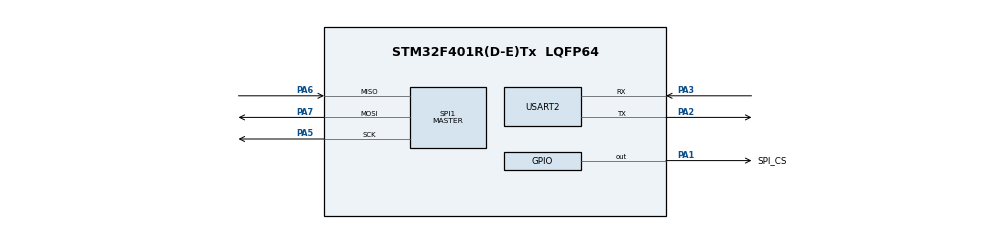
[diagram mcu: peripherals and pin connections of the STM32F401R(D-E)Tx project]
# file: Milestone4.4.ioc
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Mcu.Family=STM32F4
Mcu.Name=STM32F401R(D-E)Tx
Mcu.Package=LQFP64
NVIC.PriorityGroup=NVIC_PRIORITYGROUP_4
PA1.GPIO_Label=SPI_CS
PA1.GPIO_Speed=GPIO_SPEED_FREQ_VERY_HIGH
PA1.PinState=GPIO_PIN_SET
PA1.Signal=GPIO_Output
PA2.Mode=Asynchronous
PA2.Signal=USART2_TX
PA3.Mode=Asynchronous
PA3.Signal=USART2_RX
PA5.Mode=Full_Duplex_Master
PA5.Signal=SPI1_SCK
PA6.Mode=Full_Duplex_Master
PA6.Signal=SPI1_MISO
PA7.Mode=Full_Duplex_Master
PA7.Signal=SPI1_MOSI
ProjectManager.HeapSize=0x200
ProjectManager.StackSize=0x400
ProjectManager.TargetToolchain=Makefile
RCC.AHBFreq_Value=16000000
RCC.APB1Freq_Value=16000000
RCC.APB2Freq_Value=16000000
RCC.CortexFreq_Value=16000000
RCC.HSE_VALUE=25000000
RCC.HSI_VALUE=16000000
RCC.LSE_VALUE=32768
RCC.SYSCLKFreq_VALUE=16000000
RCC.VCOOutputFreq_Value=192000000
SPI1.Direction=SPI_DIRECTION_2LINES
SPI1.Mode=SPI_MODE_MASTER
SPI1.VirtualType=VM_MASTER
USART2.VirtualMode=VM_ASYNC
board=custom

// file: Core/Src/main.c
/* USER CODE BEGIN Header */
/**
  ******************************************************************************
  * @file           : main.c
  * @brief          : Main program body
  ******************************************************************************
  * @attention
  *
  * Copyright (c) 2026 STMicroelectronics.
  * All rights reserved.
  *
  * This software is licensed under terms that can be found in the LICENSE file
  * in the root directory of this software component.
  * If no LICENSE file comes with this software, it is provided AS-IS.
  *
  ******************************************************************************
  */
/* USER CODE END Header */
#include "main.h"
#include <stddef.h>
#include <string.h>

void UART_SendAndReadData(USART_TypeDef *USARTX, const uint8_t *data, size_t length);
void FGPA_WriteRegister(uint8_t addr, uint8_t write);
uint8_t FGPA_ReadRegister(uint8_t addr);

void SystemClock_Config(void);
static void MX_GPIO_Init(void);
static void MX_SPI1_Init(void);
static void MX_USART2_UART_Init(void);

int main(void)
{

  /* MCU Configuration--------------------------------------------------------*/

  /* Reset of all peripherals, Initializes the Flash interface and the Systick. */
  LL_APB2_GRP1_EnableClock(LL_APB2_GRP1_PERIPH_SYSCFG);
  LL_APB1_GRP1_EnableClock(LL_APB1_GRP1_PERIPH_PWR);

  /* System interrupt init*/
  NVIC_SetPriorityGrouping(NVIC_PRIORITYGROUP_4);

  /* SysTick_IRQn interrupt configuration */
  NVIC_SetPriority(SysTick_IRQn, NVIC_EncodePriority(NVIC_GetPriorityGrouping(),15, 0));

  /* Configure the system clock */
  SystemClock_Config();

  /* Initialize all configured peripherals */
  MX_GPIO_Init();
  MX_SPI1_Init();
  MX_USART2_UART_Init();
  /* USER CODE BEGIN 2 */
  LL_SPI_Enable(SPI1);

  /* USER CODE END 2 */

  uint8_t addr = 0x02;

  uint8_t write = 0x03;

  uint8_t debug_a = 'A';
  uint8_t debug_b = 'B';
  uint8_t debug_c = 'C';

 // UART_SendAndReadData(USART2, &debug_a, 1);

  FGPA_WriteRegister(addr, write);

//  UART_SendAndReadData(USART2, &debug_b, 1);

  uint8_t test = FGPA_ReadRegister(addr);

//  UART_SendAndReadData(USART2, &debug_c, 1);

  UART_SendAndReadData(USART2, &test, 1);
  /* Infinite loop */
  while (1)
  {

  }
}
uint8_t FGPA_ReadRegister(uint8_t addr){

    uint8_t rx_data = 0x00 | (addr & 0x7F);
    uint8_t dummy_byte = 0x00;
    uint8_t dummy_rx;
    uint8_t byte_data;
    (void)dummy_rx;

    // Read Function for
    LL_GPIO_ResetOutputPin(GPIOA, LL_GPIO_PIN_1);
    while (!LL_SPI_IsActiveFlag_TXE(SPI1)){}
      LL_SPI_TransmitData8(SPI1, rx_data);
   //  while (LL_SPI_IsActiveFlag_BSY(SPI1)){}

    while (!LL_SPI_IsActiveFlag_RXNE(SPI1)){}
    dummy_rx = LL_SPI_ReceiveData8(SPI1);

    while (!LL_SPI_IsActiveFlag_TXE(SPI1)){}

    LL_SPI_TransmitData8(SPI1, dummy_byte);

    while (!LL_SPI_IsActiveFlag_RXNE(SPI1)){}

    byte_data = LL_SPI_ReceiveData8(SPI1);

    while (LL_SPI_IsActiveFlag_BSY(SPI1)){}

    LL_GPIO_SetOutputPin(GPIOA, LL_GPIO_PIN_1);

    return byte_data;

}

void UART_SendAndReadData(USART_TypeDef *USARTX, const uint8_t *data, size_t length){

  for (size_t i = 0; i < length; i++){
   while (!LL_USART_IsActiveFlag_TXE(USARTX));
   LL_USART_TransmitData8(USARTX, data[i]);
   //while(!LL_USART_IsActiveFlag_RXNE(USART1)){}
  //  LL_USART_ReceiveData8(USART1);
  }
 // while (!LL_USART_IsActiveFlag_TXE(USARTX));
//  LL_USART_TransmitData8(USARTX, '\n');
  while (!LL_USART_IsActiveFlag_TC(USARTX)){}
  //while(!LL_USART_IsActiveFlag_RXNE(USART1)){}
  //LL_USART_ReceiveData8(USART1);
}

void FGPA_WriteRegister(uint8_t addr, uint8_t write){
    uint8_t tx_data = 0x80 | (addr & 0x7F);
    uint8_t dummy_byte;
    uint8_t dummy_tx;
    (void)dummy_tx;
    (void) dummy_byte;

    LL_GPIO_ResetOutputPin(GPIOA, LL_GPIO_PIN_1);
    while (!LL_SPI_IsActiveFlag_TXE(SPI1)){}

    LL_SPI_TransmitData8(SPI1, tx_data);

    while (!LL_SPI_IsActiveFlag_RXNE(SPI1)){}

    dummy_byte = LL_SPI_ReceiveData8(SPI1);

    while (!LL_SPI_IsActiveFlag_TXE(SPI1)){}

    LL_SPI_TransmitData8(SPI1, write);

    while (!LL_SPI_IsActiveFlag_RXNE(SPI1)){}

    dummy_tx = LL_SPI_ReceiveData8(SPI1);

    while (LL_SPI_IsActiveFlag_BSY(SPI1)){}

    LL_GPIO_SetOutputPin(GPIOA, LL_GPIO_PIN_1);
}

void SystemClock_Config(void)
{
  LL_FLASH_SetLatency(LL_FLASH_LATENCY_0);
  while(LL_FLASH_GetLatency()!= LL_FLASH_LATENCY_0)
  {
  }
  LL_PWR_SetRegulVoltageScaling(LL_PWR_REGU_VOLTAGE_SCALE2);
  LL_RCC_HSI_SetCalibTrimming(16);
  LL_RCC_HSI_Enable();

   /* Wait till HSI is ready */
  while(LL_RCC_HSI_IsReady() != 1)
  {

  }
  LL_RCC_SetAHBPrescaler(LL_RCC_SYSCLK_DIV_1);
  LL_RCC_SetAPB1Prescaler(LL_RCC_APB1_DIV_1);
  LL_RCC_SetAPB2Prescaler(LL_RCC_APB2_DIV_1);
  LL_RCC_SetSysClkSource(LL_RCC_SYS_CLKSOURCE_HSI);

   /* Wait till System clock is ready */
  while(LL_RCC_GetSysClkSource() != LL_RCC_SYS_CLKSOURCE_STATUS_HSI)
  {

  }
  LL_Init1msTick(16000000);
  LL_SetSystemCoreClock(16000000);
  LL_RCC_SetTIMPrescaler(LL_RCC_TIM_PRESCALER_TWICE);
}

static void MX_SPI1_Init(void)
{

  LL_SPI_InitTypeDef SPI_InitStruct = {0};

  LL_GPIO_InitTypeDef GPIO_InitStruct = {0};

  /* Peripheral clock enable */
  LL_APB2_GRP1_EnableClock(LL_APB2_GRP1_PERIPH_SPI1);

  LL_AHB1_GRP1_EnableClock(LL_AHB1_GRP1_PERIPH_GPIOA);
  /**SPI1 GPIO Configuration
  PA5   ------> SPI1_SCK
  PA6   ------> SPI1_MISO
  PA7   ------> SPI1_MOSI
  */
  GPIO_InitStruct.Pin = LL_GPIO_PIN_5|LL_GPIO_PIN_6|LL_GPIO_PIN_7;
  GPIO_InitStruct.Mode = LL_GPIO_MODE_ALTERNATE;
  GPIO_InitStruct.Speed = LL_GPIO_SPEED_FREQ_VERY_HIGH;
  GPIO_InitStruct.OutputType = LL_GPIO_OUTPUT_PUSHPULL;
  GPIO_InitStruct.Pull = LL_GPIO_PULL_NO;
  GPIO_InitStruct.Alternate = LL_GPIO_AF_5;
  LL_GPIO_Init(GPIOA, &GPIO_InitStruct);

  /* SPI1 parameter configuration*/
  SPI_InitStruct.TransferDirection = LL_SPI_FULL_DUPLEX;
  SPI_InitStruct.Mode = LL_SPI_MODE_MASTER;
  SPI_InitStruct.DataWidth = LL_SPI_DATAWIDTH_8BIT;
  SPI_InitStruct.ClockPolarity = LL_SPI_POLARITY_LOW;
  SPI_InitStruct.ClockPhase = LL_SPI_PHASE_1EDGE;
  SPI_InitStruct.NSS = LL_SPI_NSS_SOFT;
  SPI_InitStruct.BaudRate = LL_SPI_BAUDRATEPRESCALER_DIV256;
  SPI_InitStruct.BitOrder = LL_SPI_MSB_FIRST;
  SPI_InitStruct.CRCCalculation = LL_SPI_CRCCALCULATION_DISABLE;
  SPI_InitStruct.CRCPoly = 10;
  LL_SPI_Init(SPI1, &SPI_InitStruct);
  LL_SPI_SetStandard(SPI1, LL_SPI_PROTOCOL_MOTOROLA);

}

static void MX_USART2_UART_Init(void)
{

  LL_USART_InitTypeDef USART_InitStruct = {0};

  LL_GPIO_InitTypeDef GPIO_InitStruct = {0};

  /* Peripheral clock enable */
  LL_APB1_GRP1_EnableClock(LL_APB1_GRP1_PERIPH_USART2);

  LL_AHB1_GRP1_EnableClock(LL_AHB1_GRP1_PERIPH_GPIOA);
  /**USART2 GPIO Configuration
  PA2   ------> USART2_TX
  PA3   ------> USART2_RX
  */
  GPIO_InitStruct.Pin = LL_GPIO_PIN_2|LL_GPIO_PIN_3;
  GPIO_InitStruct.Mode = LL_GPIO_MODE_ALTERNATE;
  GPIO_InitStruct.Speed = LL_GPIO_SPEED_FREQ_VERY_HIGH;
  GPIO_InitStruct.OutputType = LL_GPIO_OUTPUT_PUSHPULL;
  GPIO_InitStruct.Pull = LL_GPIO_PULL_NO;
  GPIO_InitStruct.Alternate = LL_GPIO_AF_7;
  LL_GPIO_Init(GPIOA, &GPIO_InitStruct);

  USART_InitStruct.BaudRate = 115200;
  USART_InitStruct.DataWidth = LL_USART_DATAWIDTH_8B;
  USART_InitStruct.StopBits = LL_USART_STOPBITS_1;
  USART_InitStruct.Parity = LL_USART_PARITY_NONE;
  USART_InitStruct.TransferDirection = LL_USART_DIRECTION_TX_RX;
  USART_InitStruct.HardwareFlowControl = LL_USART_HWCONTROL_NONE;
  USART_InitStruct.OverSampling = LL_USART_OVERSAMPLING_16;
  LL_USART_Init(USART2, &USART_InitStruct);
  LL_USART_ConfigAsyncMode(USART2);
  LL_USART_Enable(USART2);

}

static void MX_GPIO_Init(void)
{
  LL_GPIO_InitTypeDef GPIO_InitStruct = {0};

  /* GPIO Ports Clock Enable */
  LL_AHB1_GRP1_EnableClock(LL_AHB1_GRP1_PERIPH_GPIOA);

  /**/
  LL_GPIO_SetOutputPin(SPI_CS_GPIO_Port, SPI_CS_Pin);

  /**/
  GPIO_InitStruct.Pin = SPI_CS_Pin;
  GPIO_InitStruct.Mode = LL_GPIO_MODE_OUTPUT;
  GPIO_InitStruct.Speed = LL_GPIO_SPEED_FREQ_VERY_HIGH;
  GPIO_InitStruct.OutputType = LL_GPIO_OUTPUT_PUSHPULL;
  GPIO_InitStruct.Pull = LL_GPIO_PULL_NO;
  LL_GPIO_Init(SPI_CS_GPIO_Port, &GPIO_InitStruct);

}

void Error_Handler(void)
{
  __disable_irq();
  while (1)
  {
  }
}
